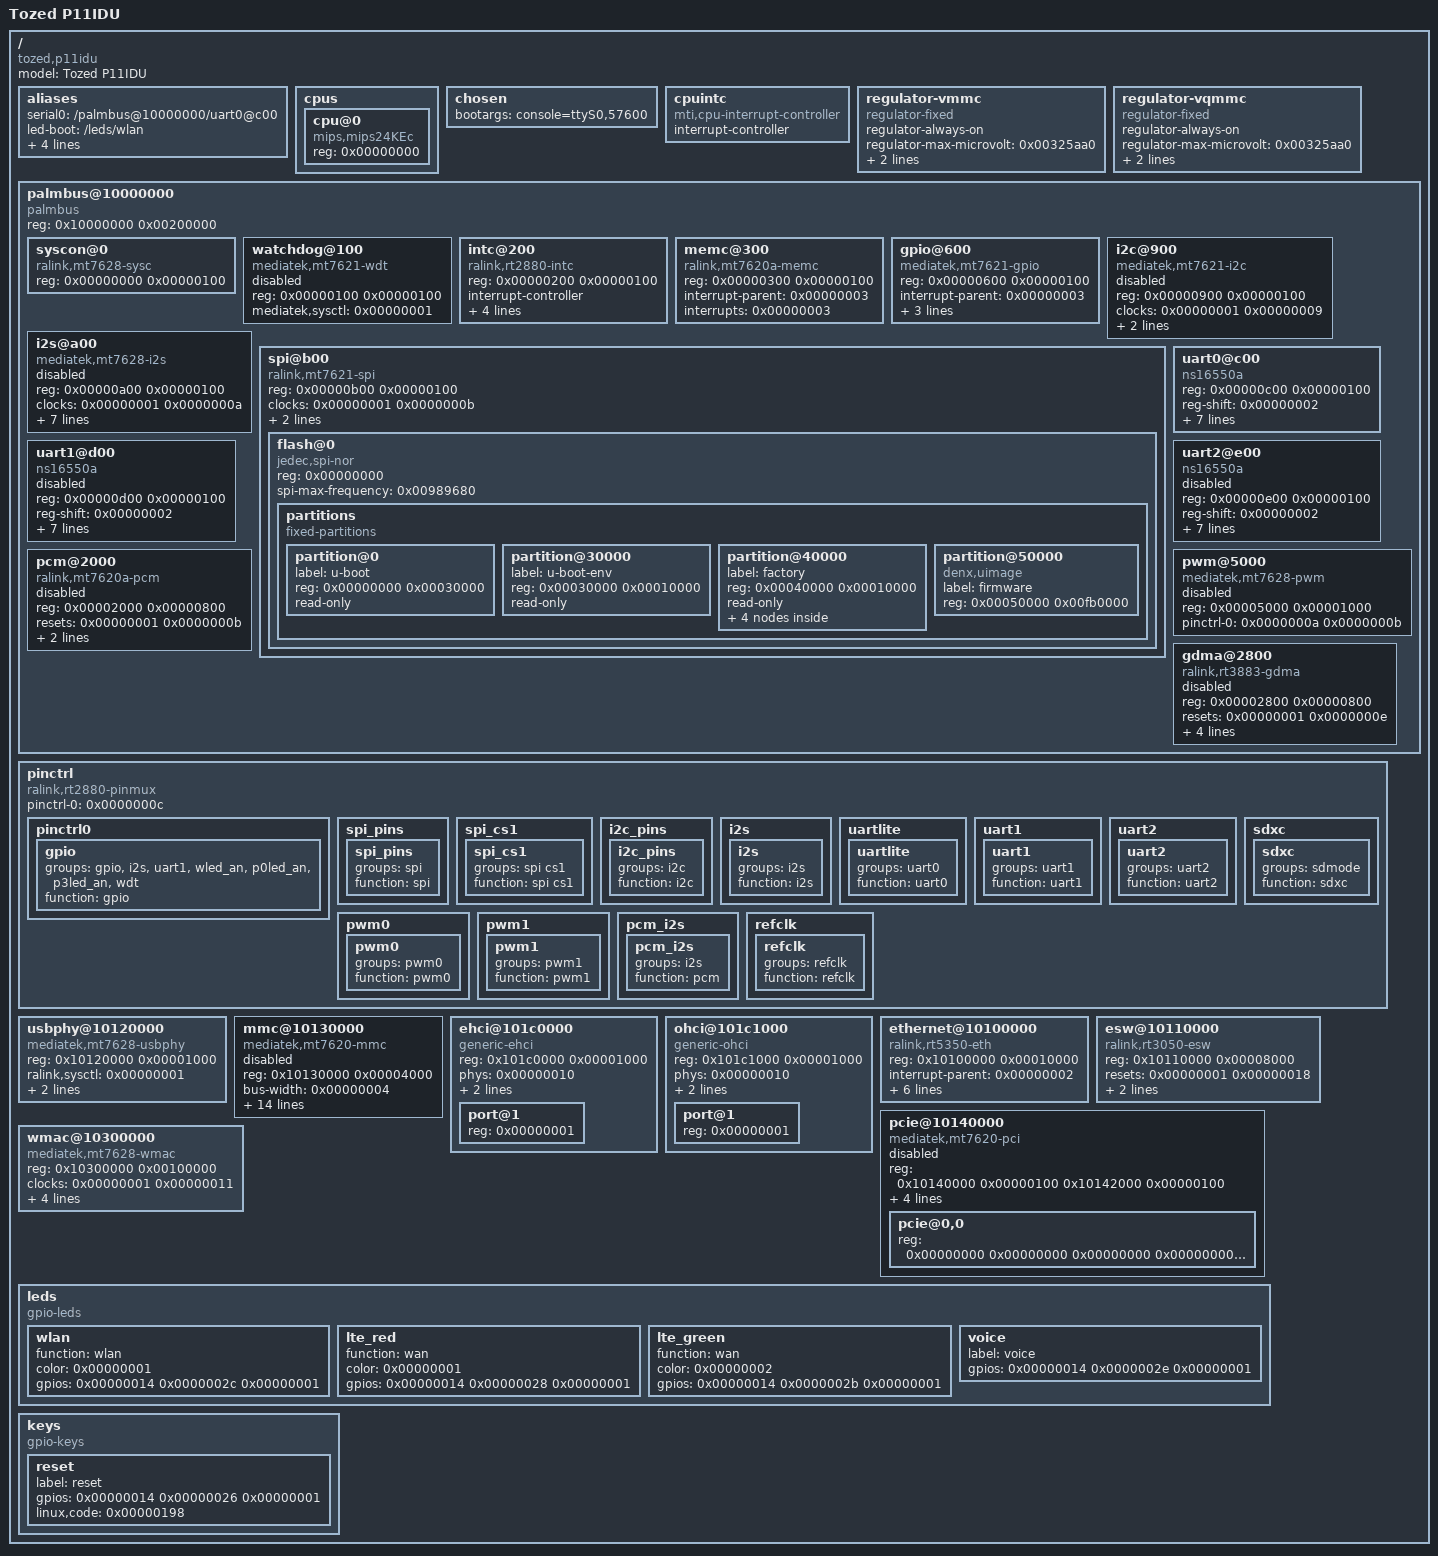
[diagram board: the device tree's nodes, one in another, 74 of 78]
/*
 * Decompiled from the running device's /sys/firmware/fdt
 * Tozed P11IDU - OpenWrt 24.10-SNAPSHOT r0-97f7026 - kernel 6.6.157
 * Original DTB: 9118 bytes, retrieved over telnet 2 Oct 2026.
 *
 * Machine-decompiled without dtc. Review and reformat before upstreaming.
 */
/dts-v1/;

/ {
  #address-cells = <0x00000001>;
  #size-cells = <0x00000001>;
  compatible = "tozed,p11idu" "mediatek,mt7628an-soc";
  model = "Tozed P11IDU";
  aliases {
    serial0 = "/palmbus@10000000/uart0@c00";
    led-boot = "/leds/wlan";
    led-failsafe = "/leds/wlan";
    led-running = "/leds/wlan";
    led-upgrade = "/leds/wlan";
    label-mac-device = "/ethernet@10100000";
  };
  cpus {
    #address-cells = <0x00000001>;
    #size-cells = <0x00000000>;
    cpu@0 {
      compatible = "mips,mips24KEc";
      reg = <0x00000000>;
    };
  };
  chosen {
    bootargs = "console=ttyS0,57600";
  };
  cpuintc {
    #address-cells = <0x00000000>;
    #interrupt-cells = <0x00000001>;
    interrupt-controller;
    compatible = "mti,cpu-interrupt-controller";
    phandle = <0x00000002>;
  };
  regulator-vmmc {
    compatible = "regulator-fixed";
    regulator-always-on;
    regulator-max-microvolt = <0x00325aa0>;
    regulator-min-microvolt = <0x00325aa0>;
    regulator-name = "mmc_power";
    phandle = <0x0000000e>;
  };
  regulator-vqmmc {
    compatible = "regulator-fixed";
    regulator-always-on;
    regulator-max-microvolt = <0x00325aa0>;
    regulator-min-microvolt = <0x00325aa0>;
    regulator-name = "mmc_io";
    phandle = <0x0000000f>;
  };
  palmbus@10000000 {
    compatible = "palmbus";
    reg = <0x10000000 0x00200000>;
    ranges = <0x00000000 0x10000000 0x001fffff>;
    #address-cells = <0x00000001>;
    #size-cells = <0x00000001>;
    syscon@0 {
      compatible = "ralink,mt7628-sysc" "ralink,mt7688-sysc" "syscon";
      reg = <0x00000000 0x00000100>;
      #clock-cells = <0x00000001>;
      #reset-cells = <0x00000001>;
      phandle = <0x00000001>;
    };
    watchdog@100 {
      compatible = "mediatek,mt7621-wdt";
      reg = <0x00000100 0x00000100>;
      mediatek,sysctl = <0x00000001>;
      status = "disabled";
    };
    intc@200 {
      compatible = "ralink,rt2880-intc";
      reg = <0x00000200 0x00000100>;
      interrupt-controller;
      #interrupt-cells = <0x00000001>;
      interrupt-parent = <0x00000002>;
      interrupts = <0x00000002>;
      ralink,intc-registers = <0x0000009c 0x000000a0 0x0000006c 0x000000a4 0x00000080 0x00000078>;
      phandle = <0x00000003>;
    };
    memc@300 {
      compatible = "ralink,mt7620a-memc" "ralink,rt3050-memc";
      reg = <0x00000300 0x00000100>;
      interrupt-parent = <0x00000003>;
      interrupts = <0x00000003>;
    };
    gpio@600 {
      compatible = "mediatek,mt7621-gpio";
      reg = <0x00000600 0x00000100>;
      interrupt-parent = <0x00000003>;
      interrupts = <0x00000006>;
      #interrupt-cells = <0x00000002>;
      interrupt-controller;
      gpio-controller;
      #gpio-cells = <0x00000002>;
      phandle = <0x00000014>;
    };
    i2c@900 {
      compatible = "mediatek,mt7621-i2c";
      reg = <0x00000900 0x00000100>;
      clocks = <0x00000001 0x00000009>;
      clock-names = "i2c";
      resets = <0x00000001 0x00000010>;
      reset-names = "i2c";
      #address-cells = <0x00000001>;
      #size-cells = <0x00000000>;
      status = "disabled";
      pinctrl-names = "default";
      pinctrl-0 = <0x00000004>;
    };
    i2s@a00 {
      compatible = "mediatek,mt7628-i2s";
      reg = <0x00000a00 0x00000100>;
      clocks = <0x00000001 0x0000000a>;
      resets = <0x00000001 0x00000011>;
      reset-names = "i2s";
      interrupt-parent = <0x00000003>;
      interrupts = <0x0000000a>;
      txdma-req = <0x00000002>;
      rxdma-req = <0x00000003>;
      dmas = <0x00000005 0x00000004 0x00000005 0x00000006>;
      dma-names = "tx" "rx";
      status = "disabled";
    };
    spi@b00 {
      compatible = "ralink,mt7621-spi";
      reg = <0x00000b00 0x00000100>;
      clocks = <0x00000001 0x0000000b>;
      clock-names = "spi";
      resets = <0x00000001 0x00000012>;
      reset-names = "spi";
      #address-cells = <0x00000001>;
      #size-cells = <0x00000000>;
      pinctrl-names = "default";
      pinctrl-0 = <0x00000006>;
      status = "okay";
      flash@0 {
        compatible = "jedec,spi-nor";
        reg = <0x00000000>;
        spi-max-frequency = <0x00989680>;
        partitions {
          compatible = "fixed-partitions";
          #address-cells = <0x00000001>;
          #size-cells = <0x00000001>;
          partition@0 {
            label = "u-boot";
            reg = <0x00000000 0x00030000>;
            read-only;
          };
          partition@30000 {
            label = "u-boot-env";
            reg = <0x00030000 0x00010000>;
            read-only;
          };
          partition@40000 {
            label = "factory";
            reg = <0x00040000 0x00010000>;
            read-only;
            nvmem-layout {
              compatible = "fixed-layout";
              #address-cells = <0x00000001>;
              #size-cells = <0x00000001>;
              eeprom@0 {
                reg = <0x00000000 0x00000400>;
                phandle = <0x00000013>;
              };
              macaddr@4 {
                compatible = "mac-base";
                reg = <0x00000004 0x00000006>;
                #nvmem-cell-cells = <0x00000001>;
              };
              macaddr@28 {
                compatible = "mac-base";
                reg = <0x00000028 0x00000006>;
                #nvmem-cell-cells = <0x00000001>;
                phandle = <0x00000012>;
              };
            };
          };
          partition@50000 {
            compatible = "denx,uimage";
            label = "firmware";
            reg = <0x00050000 0x00fb0000>;
          };
        };
      };
    };
    uart0@c00 {
      compatible = "ns16550a";
      reg = <0x00000c00 0x00000100>;
      reg-shift = <0x00000002>;
      reg-io-width = <0x00000004>;
      no-loopback-test;
      clocks = <0x00000001 0x0000000d>;
      resets = <0x00000001 0x0000000c>;
      interrupt-parent = <0x00000003>;
      interrupts = <0x00000014>;
      pinctrl-names = "default";
      pinctrl-0 = <0x00000007>;
    };
    uart1@d00 {
      compatible = "ns16550a";
      reg = <0x00000d00 0x00000100>;
      reg-shift = <0x00000002>;
      reg-io-width = <0x00000004>;
      no-loopback-test;
      clocks = <0x00000001 0x0000000e>;
      resets = <0x00000001 0x00000013>;
      interrupt-parent = <0x00000003>;
      interrupts = <0x00000015>;
      pinctrl-names = "default";
      pinctrl-0 = <0x00000008>;
      status = "disabled";
    };
    uart2@e00 {
      compatible = "ns16550a";
      reg = <0x00000e00 0x00000100>;
      reg-shift = <0x00000002>;
      reg-io-width = <0x00000004>;
      no-loopback-test;
      clocks = <0x00000001 0x0000000f>;
      resets = <0x00000001 0x00000014>;
      interrupt-parent = <0x00000003>;
      interrupts = <0x00000016>;
      pinctrl-names = "default";
      pinctrl-0 = <0x00000009>;
      status = "disabled";
    };
    pwm@5000 {
      compatible = "mediatek,mt7628-pwm";
      reg = <0x00005000 0x00001000>;
      #pwm-cells = <0x00000002>;
      pinctrl-names = "default";
      pinctrl-0 = <0x0000000a 0x0000000b>;
      status = "disabled";
    };
    pcm@2000 {
      compatible = "ralink,mt7620a-pcm";
      reg = <0x00002000 0x00000800>;
      resets = <0x00000001 0x0000000b>;
      reset-names = "pcm";
      interrupt-parent = <0x00000003>;
      interrupts = <0x00000004>;
      status = "disabled";
    };
    gdma@2800 {
      compatible = "ralink,rt3883-gdma";
      reg = <0x00002800 0x00000800>;
      resets = <0x00000001 0x0000000e>;
      reset-names = "dma";
      interrupt-parent = <0x00000003>;
      interrupts = <0x00000007>;
      #dma-cells = <0x00000001>;
      #dma-channels = <0x00000010>;
      #dma-requests = <0x00000010>;
      status = "disabled";
      phandle = <0x00000005>;
    };
  };
  pinctrl {
    compatible = "ralink,rt2880-pinmux";
    pinctrl-names = "default";
    pinctrl-0 = <0x0000000c>;
    pinctrl0 {
      phandle = <0x0000000c>;
      gpio {
        groups = "gpio" "i2s" "uart1" "wled_an" "p0led_an" "p3led_an" "wdt";
        function = "gpio";
      };
    };
    spi_pins {
      phandle = <0x00000006>;
      spi_pins {
        groups = "spi";
        function = "spi";
      };
    };
    spi_cs1 {
      spi_cs1 {
        groups = "spi cs1";
        function = "spi cs1";
      };
    };
    i2c_pins {
      phandle = <0x00000004>;
      i2c_pins {
        groups = "i2c";
        function = "i2c";
      };
    };
    i2s {
      i2s {
        groups = "i2s";
        function = "i2s";
      };
    };
    uartlite {
      phandle = <0x00000007>;
      uartlite {
        groups = "uart0";
        function = "uart0";
      };
    };
    uart1 {
      phandle = <0x00000008>;
      uart1 {
        groups = "uart1";
        function = "uart1";
      };
    };
    uart2 {
      phandle = <0x00000009>;
      uart2 {
        groups = "uart2";
        function = "uart2";
      };
    };
    sdxc {
      phandle = <0x0000000d>;
      sdxc {
        groups = "sdmode";
        function = "sdxc";
      };
    };
    pwm0 {
      phandle = <0x0000000a>;
      pwm0 {
        groups = "pwm0";
        function = "pwm0";
      };
    };
    pwm1 {
      phandle = <0x0000000b>;
      pwm1 {
        groups = "pwm1";
        function = "pwm1";
      };
    };
    pcm_i2s {
      pcm_i2s {
        groups = "i2s";
        function = "pcm";
      };
    };
    refclk {
      refclk {
        groups = "refclk";
        function = "refclk";
      };
    };
  };
  usbphy@10120000 {
    compatible = "mediatek,mt7628-usbphy" "mediatek,mt7620-usbphy";
    reg = <0x10120000 0x00001000>;
    #phy-cells = <0x00000000>;
    ralink,sysctl = <0x00000001>;
    resets = <0x00000001 0x00000016 0x00000001 0x00000019>;
    reset-names = "host" "device";
    phandle = <0x00000010>;
  };
  mmc@10130000 {
    compatible = "mediatek,mt7620-mmc" "ralink,mt7620-sdhci";
    reg = <0x10130000 0x00004000>;
    bus-width = <0x00000004>;
    max-frequency = <0x02dc6c00>;
    cap-mmc-highspeed;
    cap-sd-highspeed;
    disable-wp;
    no-1-8-v;
    clocks = <0x00000001 0x00000010 0x00000001 0x00000010>;
    clock-names = "source" "hclk";
    interrupt-parent = <0x00000003>;
    interrupts = <0x0000000e>;
    pinctrl-names = "default" "state_uhs";
    pinctrl-0 = <0x0000000d>;
    pinctrl-1 = <0x0000000d>;
    resets = <0x00000001 0x0000001e>;
    reset-names = "hrst";
    vmmc-supply = <0x0000000e>;
    vqmmc-supply = <0x0000000f>;
    status = "disabled";
  };
  ehci@101c0000 {
    #address-cells = <0x00000001>;
    #size-cells = <0x00000000>;
    compatible = "generic-ehci";
    reg = <0x101c0000 0x00001000>;
    phys = <0x00000010>;
    phy-names = "usb";
    interrupt-parent = <0x00000003>;
    interrupts = <0x00000012>;
    port@1 {
      reg = <0x00000001>;
      #trigger-source-cells = <0x00000000>;
    };
  };
  ohci@101c1000 {
    #address-cells = <0x00000001>;
    #size-cells = <0x00000000>;
    compatible = "generic-ohci";
    reg = <0x101c1000 0x00001000>;
    phys = <0x00000010>;
    phy-names = "usb";
    interrupt-parent = <0x00000003>;
    interrupts = <0x00000012>;
    port@1 {
      reg = <0x00000001>;
      #trigger-source-cells = <0x00000000>;
    };
  };
  ethernet@10100000 {
    compatible = "ralink,rt5350-eth";
    reg = <0x10100000 0x00010000>;
    interrupt-parent = <0x00000002>;
    interrupts = <0x00000005>;
    resets = <0x00000001 0x00000015 0x00000001 0x00000017>;
    reset-names = "fe" "esw";
    mediatek,switch = <0x00000011>;
    nvmem-cells = <0x00000012>;
    nvmem-cell-names = "mac-address";
  };
  esw@10110000 {
    compatible = "ralink,rt3050-esw";
    reg = <0x10110000 0x00008000>;
    resets = <0x00000001 0x00000018>;
    reset-names = "ephy";
    interrupt-parent = <0x00000003>;
    interrupts = <0x00000011>;
    phandle = <0x00000011>;
  };
  pcie@10140000 {
    compatible = "mediatek,mt7620-pci";
    reg = <0x10140000 0x00000100 0x10142000 0x00000100>;
    #address-cells = <0x00000003>;
    #size-cells = <0x00000002>;
    interrupt-parent = <0x00000002>;
    interrupts = <0x00000004>;
    resets = <0x00000001 0x0000001a>;
    reset-names = "pcie0";
    status = "disabled";
    device_type = "pci";
    bus-range = <0x00000000 0x000000ff>;
    ranges = <0x02000000 0x00000000 0x00000000 0x20000000 0x00000000 0x10000000 0x01000000 0x00000000 0x00000000 0x10160000 0x00000000 0x00010000>;
    pcie@0,0 {
      reg = <0x00000000 0x00000000 0x00000000 0x00000000 0x00000000>;
      #address-cells = <0x00000003>;
      #size-cells = <0x00000002>;
      device_type = "pci";
      ranges;
    };
  };
  wmac@10300000 {
    compatible = "mediatek,mt7628-wmac";
    reg = <0x10300000 0x00100000>;
    clocks = <0x00000001 0x00000011>;
    interrupt-parent = <0x00000002>;
    interrupts = <0x00000006>;
    status = "okay";
    nvmem-cells = <0x00000013>;
    nvmem-cell-names = "eeprom";
  };
  leds {
    compatible = "gpio-leds";
    wlan {
      function = "wlan";
      color = <0x00000001>;
      gpios = <0x00000014 0x0000002c 0x00000001>;
    };
    lte_red {
      function = "wan";
      color = <0x00000001>;
      gpios = <0x00000014 0x00000028 0x00000001>;
    };
    lte_green {
      function = "wan";
      color = <0x00000002>;
      gpios = <0x00000014 0x0000002b 0x00000001>;
    };
    voice {
      label = "voice";
      gpios = <0x00000014 0x0000002e 0x00000001>;
    };
  };
  keys {
    compatible = "gpio-keys";
    reset {
      label = "reset";
      gpios = <0x00000014 0x00000026 0x00000001>;
      linux,code = <0x00000198>;
    };
  };
};
